# ATA5835 device description
Architecture: AVR8; Family: megaAVR
Registers are 8-bit, access not given, no defined reset value unless marked. A register's access mark holds for its fields unless they carry their own. Offsets are from the block's base; [hi:lo] are bit positions.

## TIMER0_WDT
Instances: TIMER0_WDT 0x00
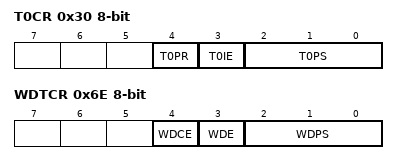
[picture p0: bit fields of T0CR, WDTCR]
0x30 T0CR — Timer0 Control Register
  [4] T0PR — Timer0 Prescaler Reset
  [3] T0IE — Timer0 Interrupt Enable
  [2:0] T0PS — Timer0 Prescaler Select
0x4F T0IFR — Timer0 Interrupt Flag Register
  [0] T0F — Timer0 Flag
0x6E WDTCR — Watchdog Timer0 Control Register
  [4] WDCE — Watchdog Change Enable
  [3] WDE — Watchdog Enable
  [2:0] WDPS — Watchdog Prescaler Select

## TIMER1
Instances: TIMER1 0x00
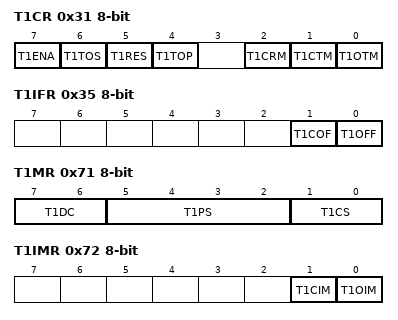
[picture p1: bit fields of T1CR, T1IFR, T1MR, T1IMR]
0x31 T1CR — Timer1 Control Register
  [7] T1ENA — Timer1 Enable
  [6] T1TOS — Timer1 Toggle with Start
  [5] T1RES — Timer1 Reset
  [4] T1TOP — Timer1 Toggle Output Preset
  [2] T1CRM — Timer1 Compare Reset Mask
  [1] T1CTM — Timer1 Compare Toggle Mask
  [0] T1OTM — Timer1 Overflow Toggle Mask
0x35 T1IFR — Timer1 Interrupt Flag Register
  [1] T1COF — Timer1 Compare Flag
  [0] T1OFF — Timer1 Overflow Flag
0x6F T1CNT — Timer1 Counter Register
0x70 T1COR — Timer1 Compare Register
0x71 T1MR — Timer1 Mode Register
  [7:6] T1DC — Timer1 Duty Cycle
  [5:2] T1PS — Timer1 Prescaler Select
  [1:0] T1CS — Timer1 Clock Select
    0=clk_src; 1=clk_frc; 2=clk_T; 3=clk_xto4
0x72 T1IMR — Timer1 Interrupt Mask Register
  [1] T1CIM — Timer1 Compare Interrupt Mask
  [0] T1OIM — Timer1 Overflow Interrupt Mask

## TIMER2
Instances: TIMER2 0x00
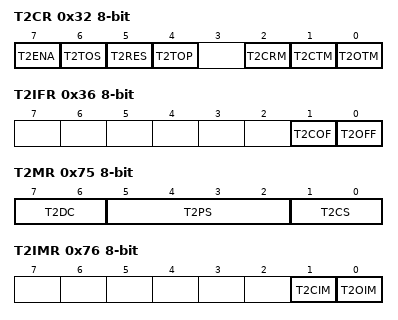
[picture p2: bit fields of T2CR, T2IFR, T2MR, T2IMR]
0x32 T2CR — Timer2 Control Register
  [7] T2ENA — Timer2 Enable
  [6] T2TOS — Timer2 Toggle with Start
  [5] T2RES — Timer2 Reset
  [4] T2TOP — Timer2 Toggle Output Preset
  [2] T2CRM — Timer2 Compare Reset Mask
  [1] T2CTM — Timer2 Compare Toggle Mask
  [0] T2OTM — Timer2 Overflow Toggle Mask
0x36 T2IFR — Timer2 Interrupt Flag Register
  [1] T2COF — Timer2 Compare Flag
  [0] T2OFF — Timer2 Overflow Flag
0x73 T2CNT — Timer2 Counter Register
0x74 T2COR — Timer2 Compare Register
0x75 T2MR — Timer2 Mode Register
  [7:6] T2DC — Timer2 Duty Cycle
  [5:2] T2PS — Timer2 Prescaler Select
  [1:0] T2CS — Timer2 Clock Select
    0=clk_src; 1=clk_vdiv; 2=clk_T; 3=clk_xto4
0x76 T2IMR — Timer2 Interrupt Mask Register
  [1] T2CIM — Timer2 Compare Interrupt Mask
  [0] T2OIM — Timer2 Overflow Interrupt Mask

## TIMER3
Instances: TIMER3 0x00
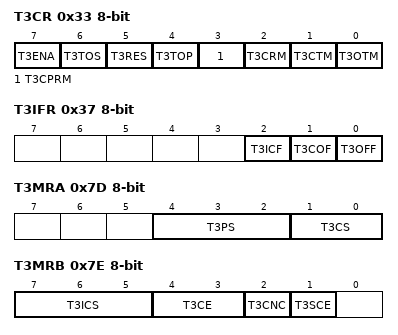
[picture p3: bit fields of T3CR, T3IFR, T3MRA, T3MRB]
0x33 T3CR — Timer3 Control Register
  [7] T3ENA — Timer3 Enable
  [6] T3TOS — Timer3 Toggle with Start
  [5] T3RES — Timer3 Reset
  [4] T3TOP — Timer3 Toggle Output Preset
  [3] T3CPRM — Timer3 Capture Reset Mask
  [2] T3CRM — Timer3 Compare Reset Mask
  [1] T3CTM — Timer3 Compare Toggle Mask
  [0] T3OTM — Timer3 Overflow Toggle Mask
0x37 T3IFR — Timer3 Interrupt Flag Register
  [2] T3ICF — Timer3 Input Capture Flag
  [1] T3COF — Timer3 Compare Flag
  [0] T3OFF — Timer3 Overflow Flag
0x77 T3CNT 16-bit — Timer3 Counter
0x79 T3COR 16-bit — Timer3 Compare
0x7B T3ICR 16-bit — Timer3 Input Capture
0x7D T3MRA — Timer3 Mode Register A
  [4:2] T3PS — Timer3 Prescaler Select
  [1:0] T3CS — Timer3 Clock Select
    0=clk_frc; 1=clk_T; 2=clk_xto4; 3=clk_xto2
0x7E T3MRB — Timer3 Mode Register B
  [7:5] T3ICS — Timer3 Input Capture Select
    0=clk_T2; 1=trpa; 2=trpb; 3=ticp; 4=clk_src
  [4:3] T3CE — Timer3 Capture Edge Select
    0=disable; 1=rising edge; 2=falling edge; 3=both edges
  [2] T3CNC — Timer3 Input Capture Noise Canceller
  [1] T3SCE — Timer3 Software Capture Enable
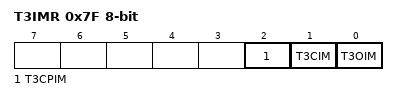
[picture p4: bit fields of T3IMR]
0x7F T3IMR — Timer3 Interrupt Mask Register
  [2] T3CPIM — Timer3 Capture Interrupt Mask
  [1] T3CIM — Timer3 Compare Interrupt Mask
  [0] T3OIM — Timer3 Overflow Interrupt Mask

## TIMER4
Instances: TIMER4 0x00
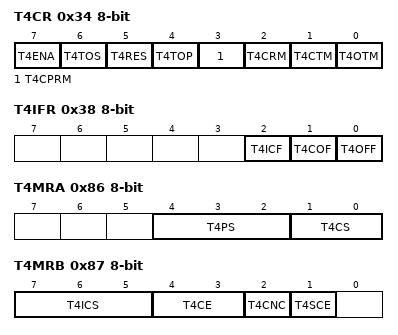
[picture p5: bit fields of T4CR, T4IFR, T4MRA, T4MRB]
0x34 T4CR — Timer4 Control Register
  [7] T4ENA — Timer4 Enable
  [6] T4TOS — Timer4 Toggle with Start
  [5] T4RES — Timer4 Reset
  [4] T4TOP — Timer4 Toggle Output Preset
  [3] T4CPRM — Timer4 Capture Reset Mask
  [2] T4CRM — Timer4 Compare Reset Mask
  [1] T4CTM — Timer4 Compare Toggle Mask
  [0] T4OTM — Timer4 Overflow Toggle Mask
0x38 T4IFR — Timer4 Interrupt Flag Register
  [2] T4ICF — Timer4 Input Capture Flag
  [1] T4COF — Timer4 Compare Flag
  [0] T4OFF — Timer4 Overflow Flag
0x80 T4CNT 16-bit — Timer4 Counter
0x82 T4COR 16-bit — Timer4 Compare
0x84 T4ICR 16-bit — Timer4 Input Capture
0x86 T4MRA — Timer4 Mode Register A
  [4:2] T4PS — Timer4 Prescaler Select
  [1:0] T4CS — Timer4 Clock Select
    0=clk_src; 1=clk_T; 2=clk_xto6; 3=clk_frc
0x87 T4MRB — Timer4 Mode Register B
  [7:5] T4ICS — Timer4 Input Capture Select
    0=clk_T2; 1=trpa; 2=trpb; 3=ticp; 4=clk_src
  [4:3] T4CE — Timer4 Capture Edge Select
    0=disable; 1=rising edge; 2=falling edge; 3=both edges
  [2] T4CNC — Timer4 Input Capture Noise Canceller
  [1] T4SCE — Timer4 Software Capture Enable
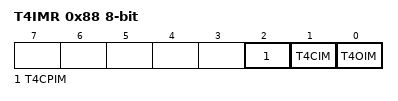
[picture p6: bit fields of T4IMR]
0x88 T4IMR — Timer4 Interrupt Mask Register
  [2] T4CPIM — Timer4 Capture Interrupt Mask
  [1] T4CIM — Timer4 Compare Interrupt Mask
  [0] T4OIM — Timer4 Overflow Interrupt Mask

## TIMER5
Instances: TIMER5 0x00
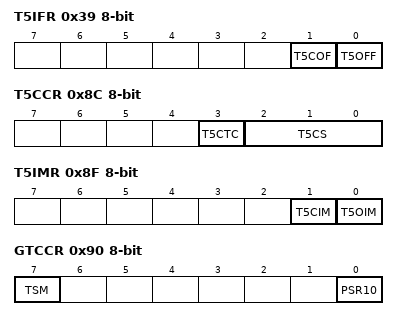
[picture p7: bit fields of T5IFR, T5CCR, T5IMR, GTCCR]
0x39 T5IFR — Timer5 Interrupt Flag Register
  [1] T5COF — Timer5 Compare Flag
  [0] T5OFF — Timer5 Overflow Flag
0x8A T5OCR 16-bit — Timer5 Output Compare
0x8C T5CCR — Timer5 Configuration and Control Register
  [3] T5CTC — Timer5 Clear Counter on Compare Match
  [2:0] T5CS — Timer5 Clock Select
    0=No Clock Source (Stopped); 1=Running, No Prescaling; 2=Running, CLK/8; 3=Running, CLK/32; 4=Running, CLK/64; 5=Running, CLK/128; 6=Running, CLK/256; 7=Running, CLK/1024
0x8D T5CNT 16-bit — Timer5 Counter
0x8F T5IMR — Timer5 Interrupt Mask Register
  [1] T5CIM — Timer5 Compare Interrupt Mask
  [0] T5OIM — Timer5 Overflow Interrupt Mask
0x90 GTCCR — General Timer/Counter Control Register
  [7] TSM — Timer Synchronization Mode
  [0] PSR10 — Prescaler Reset

## TRACE
Instances: TRACE 0x00
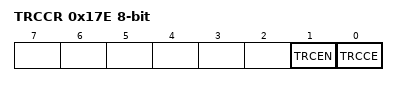
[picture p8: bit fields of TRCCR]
0x17E TRCCR — Trace Unit Control Register
  [1] TRCEN — Trace Unit Enable
  [0] TRCCE — Trace Unit Change Enable
0x17F TRCDR — Trace Unit Data Register
0x180 TRCID 16-bit — Trace Identifier

## TXM
Instances: TXM 0x00
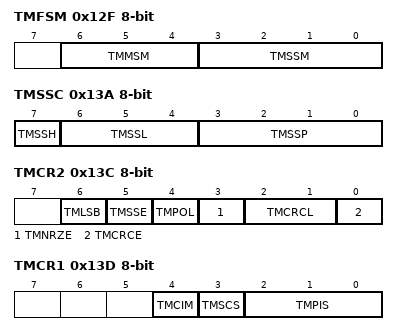
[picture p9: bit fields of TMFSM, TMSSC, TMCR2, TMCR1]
0x12F TMFSM — Tx Modulator Finite State Machine
  [6:4] TMMSM — Tx Modulator Master State Machine
  [3:0] TMSSM — Tx Modulator Sub State Machine
0x130 TMCR 16-bit — Tx Modulator CRC Result
0x132 TMCSB — Tx Modulator CRC Skip Bit Number
0x134 TMCI 16-bit — Tx Modulator CRC Init Value
0x135 TMCP 16-bit — Tx Modulator CRC Polynomial
0x137 TMSHR — Tx Modulator Shift Register
0x138 TMTL 16-bit bits used 11:0 — Tx Modulator Telegram Length
0x13A TMSSC — Tx Modulator Stop Sequence Configuration
  [7] TMSSH — Tx Modulator Stop Sequence Hold Mode
  [6:4] TMSSL — Tx Modulator Stop Sequence Length
  [3:0] TMSSP — Tx Modulator Stop Sequence Pattern
0x13B TMSR — Tx Modulator Status Register
  [0] TMTCF — Tx Modulator Transmission Complete Status Flag
0x13C TMCR2 — Tx Modulator Control Register 2
  [6] TMLSB — Tx Modulator Most Significant Bit First
  [5] TMSSE — Tx Modulator Stop Sequence Enable
  [4] TMPOL — Tx Modulator Polarity
  [3] TMNRZE — Tx Modulator NRZ Mode Enable
  [2:1] TMCRCL — Tx Modulator CRC Length
    0=CRC 4-bit; 1=CRC 8-bit; 2=CRC 16-bit
  [0] TMCRCE — Tx Modulator CRC Enable
0x13D TMCR1 — Tx Modulator Control Register 1
  [4] TMCIM — Tx Modulator Transmission Complete Interrupt Mask
  [3] TMSCS — Tx Modulator Serial Output Clock Select
  [2:0] TMPIS — Tx Modulator Port Interface Select
    0=Port C3; 1=M2 - Toggle Register Timer2; 2=M3 - Toggle Register Timer3; 3=M4 - Toggle Register Timer4; 4=SO Tx Modulator Serial Output; 5=M1 - Toggle Register Timer1

## VMON
Instances: VMON 0x00
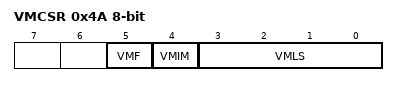
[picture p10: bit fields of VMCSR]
0x4A VMCSR — Voltage Monitor Control and Status Register
  [5] VMF — Voltage Monitor Flag
  [4] VMIM — Voltage Monitor Interrupt Mask
  [3:0] VMLS — Voltage Monitor Level Select
    0=disable; 1=2.0V; 2=2.1V; 3=2.2V; 4=2.3V; 5=2.4V; 6=2.5V; 7=2.6V; 8=2.7V; 9=2.8V; 10=2.9V; 11=3.0V; 12=3.1V; 13=3.2V; 14=3.3V; 15=3.4V
